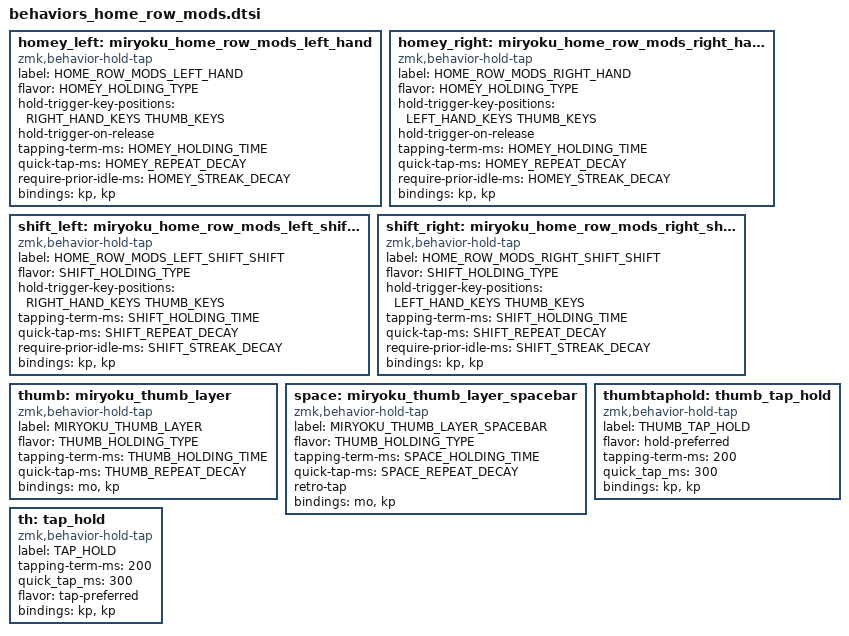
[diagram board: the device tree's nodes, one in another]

    #define L_PINKY homey_left LGUI
    #define L_RING  homey_left LALT
    #define L_LONG  homey_left LCTRL
    #define L_INDEX shift_left LSHFT

    #define R_PINKY homey_right LGUI
    #define R_RING  homey_right LALT
    #define R_LONG  homey_right LCTRL
    #define R_INDEX shift_right LSHFT

    //
    // HOMEY_HOLDING_TYPE defines the flavor of ZMK hold-tap behavior to use
    // for the pinky, ring, and middle fingers (which are assigned to Super,
    // Alt, and Ctrl respectively in the Miryoku system) on home row keys.
    //
    #ifndef HOMEY_HOLDING_TYPE
    #define HOMEY_HOLDING_TYPE "tap-preferred"
    #endif

    //
    // HOMEY_HOLDING_TIME defines how long you need to hold (milliseconds)
    // home row mod keys in order to send their modifiers to the computer
    // (i.e. "register" them) for mod-click mouse usage (e.g. Ctrl-Click).
    //
    #ifndef HOMEY_HOLDING_TIME
    #define HOMEY_HOLDING_TIME 300 // TAPPING_TERM + ALLOW_CROSSOVER_AFTER
    #endif

    //
    // HOMEY_STREAK_DECAY defines how long you need to wait (milliseconds)
    // after typing before you can use home row mods again.  It prevents
    // unintended activation of home row mods when you're actively typing.
    //
    #ifndef HOMEY_STREAK_DECAY
    #define HOMEY_STREAK_DECAY 170 // global-quick-tap-ms
    #endif

    //
    // HOMEY_REPEAT_DECAY defines how much time you have left (milliseconds)
    // after tapping a key to hold it again in order to make it auto-repeat.
    //
    #ifndef HOMEY_REPEAT_DECAY
    #define HOMEY_REPEAT_DECAY 300 // "tap then hold" for key auto-repeat
    #endif

    //
    // SHIFT_HOLDING_TYPE defines the flavor of ZMK hold-tap behavior to use
    // for index fingers (which Miryoku assigns to Shift) on home row keys.
    //
    // NOTE: The "tap-preferred" flavor of ZMK hold-tap for index finger keys
    // allows faster activation of the Shift modifier (without having to wait
    // for the modified key to be released as the "balanced" flavor requires).
    // Typing streaks and the `hold-trigger-on-release` setting are disabled
    // for the index fingers so as not to hinder their speed and dexterity.
    //
    #ifndef SHIFT_HOLDING_TYPE
    #define SHIFT_HOLDING_TYPE "tap-preferred"
    #endif

    //
    // SHIFT_HOLDING_TIME defines how long you need to hold (milliseconds)
    // index finger keys in order to send their modifiers to the computer
    // (i.e. "register" them) for mod-click mouse usage (e.g. Shift-Click).
    //
    // CAUTION: You'll need to perform inward rolls from pinky->ring->middle
    // fingers toward the index fingers when activating multiple modifiers
    // because `hold-trigger-on-release` is disabled for the index fingers.
    // Otherwise, you may be surprised that the index fingers' modifier is
    // sent immediately without the rest of your multi-mod chord when you
    // perform outward rolls from your index fingers toward your pinkies.
    //
    #ifndef SHIFT_HOLDING_TIME
    #define SHIFT_HOLDING_TIME 220
    #endif

    //
    // SHIFT_STREAK_DECAY defines how long you need to wait (milliseconds)
    // after typing before you can use home row mods again.  It prevents
    // unintended activation of home row mods when you're actively typing.
    //
    #ifndef SHIFT_STREAK_DECAY
    #define SHIFT_STREAK_DECAY 150 // global-quick-tap-ms
    #endif

    //
    // SHIFT_REPEAT_DECAY defines how much time you have left (milliseconds)
    // after tapping a key to hold it again in order to make it auto-repeat.
    //
    #ifndef SHIFT_REPEAT_DECAY
    #define SHIFT_REPEAT_DECAY 300 // "tap then hold" for key auto-repeat
    #endif

    //
    // THUMB_HOLDING_TYPE defines the flavor of ZMK hold-tap behavior to use
    // for the thumbs (which are assigned to 6 layers in the Miryoku system).
    //
    // NOTE: The "balanced" flavor of ZMK hold-tap provides instant modifier
    // activation for the symbol layer (if the tapped symbol key is released
    // while the thumb layer key is still held down) for quicker programming.
    //
    #ifndef THUMB_HOLDING_TYPE
    #define THUMB_HOLDING_TYPE "balanced"
    #endif

    //
    // THUMB_HOLDING_TIME defines how long you need to hold (milliseconds)
    // a thumb key to activate a layer.  Shorter holds are treated as taps.
    //
    #ifndef THUMB_HOLDING_TIME
    #define THUMB_HOLDING_TIME 200
    #endif

    //
    // THUMB_REPEAT_DECAY defines how much time you have left (milliseconds)
    // after tapping a key to hold it again in order to make it auto-repeat.
    //
    #ifndef THUMB_REPEAT_DECAY
    #define THUMB_REPEAT_DECAY 300 // "tap then hold" for key auto-repeat
    #endif

    //
    // SPACE_HOLDING_TIME defines how long you need to hold (milliseconds)
    // the space thumb key to activate.  Shorter holds are treated as taps.
    //
    #ifndef SPACE_HOLDING_TIME
    #define SPACE_HOLDING_TIME 200
    #endif

    //
    // SPACE_REPEAT_DECAY defines how much time you have left (milliseconds)
    // after tapping a key to hold it again in order to make it auto-repeat.
    //
    #ifndef SPACE_REPEAT_DECAY
    #define SPACE_REPEAT_DECAY 200 // "tap then hold" for key auto-repeat
    #endif

    //
    // Advantage 360 Pro key positions index for positional hold-tap
    //
    // |------------------------|------------------------|
    // | LEFT_HAND_KEYS         |        RIGHT_HAND_KEYS |
    // |                        |                        |
    // |  0  1  2  3  4  5  6   |   7  8  9  10 11 12 13 |
    // | 14 15 16 17 18 19 20   |   21 22 23 24 25 26 27 |
    // | 28 29 30 31 32 33 34   |   39 40 41 42 43 44 45 |
    // | 46 47 48 49 50 51      |      54 55 56 57 58 59 |
    // | 60 61 62 63 64         |         71 72 73 74 75 |
    // |                  35 36 | 37 38                  |
    // |               65 66 52 | 53 69 70               |
    // |               65 66 67 | 68 69 70               |
    // |------------------------|------------------------|
    //
    #define LEFT_HAND_KEYS      \
          0  1  2  3  4  5  6   \
          14 15 16 17 18 19 20  \
          28 29 30 31 32 33 34  \
          46 47 48 49 50 51     \
          60 61 62 63 64
    #define RIGHT_HAND_KEYS     \
                                    7  8  9 10 11 12 13  \ 
                                    21 22 23 24 25 26 27 \
                                    39 40 41 42 43 44 45 \
                                       54 55 56 57 58 59 \
                                          71 72 73 74 75
    #define THUMB_KEYS          \
                          35 36   37 38      \
                             52   53         \
                       65 66 67   68 69 70


    //
    // Home row mod-tap keys for all except index fingers
    //
    homey_left: miryoku_home_row_mods_left_hand {
        compatible = "zmk,behavior-hold-tap";
        label = "HOME_ROW_MODS_LEFT_HAND";
        flavor = HOMEY_HOLDING_TYPE;
        hold-trigger-key-positions = <RIGHT_HAND_KEYS THUMB_KEYS>;
        hold-trigger-on-release; // wait for other home row mods
        tapping-term-ms = <HOMEY_HOLDING_TIME>;
        quick-tap-ms = <HOMEY_REPEAT_DECAY>;
        require-prior-idle-ms = <HOMEY_STREAK_DECAY>;
        #binding-cells = <2>;
        bindings = <&kp>, <&kp>;
    };
    homey_right: miryoku_home_row_mods_right_hand {
        compatible = "zmk,behavior-hold-tap";
        label = "HOME_ROW_MODS_RIGHT_HAND";
        flavor = HOMEY_HOLDING_TYPE;
        hold-trigger-key-positions = <LEFT_HAND_KEYS THUMB_KEYS>;
        hold-trigger-on-release; // wait for other home row mods
        tapping-term-ms = <HOMEY_HOLDING_TIME>;
        quick-tap-ms = <HOMEY_REPEAT_DECAY>;
        require-prior-idle-ms = <HOMEY_STREAK_DECAY>;
        #binding-cells = <2>;
        bindings = <&kp>, <&kp>;
    };

    //
    // Special home row mod-tap keys for the index fingers
    //
    shift_left: miryoku_home_row_mods_left_shift_shift {
        compatible = "zmk,behavior-hold-tap";
        label = "HOME_ROW_MODS_LEFT_SHIFT_SHIFT";
        flavor = SHIFT_HOLDING_TYPE;
        hold-trigger-key-positions = <RIGHT_HAND_KEYS THUMB_KEYS>;
        //hold-trigger-on-release; // don't wait for other mods
        tapping-term-ms = <SHIFT_HOLDING_TIME>;
        quick-tap-ms = <SHIFT_REPEAT_DECAY>;
        require-prior-idle-ms = <SHIFT_STREAK_DECAY>;
        #binding-cells = <2>;
        bindings = <&kp>, <&kp>;
    };
    shift_right: miryoku_home_row_mods_right_shift_shift {
        compatible = "zmk,behavior-hold-tap";
        label = "HOME_ROW_MODS_RIGHT_SHIFT_SHIFT";
        flavor = SHIFT_HOLDING_TYPE;
        hold-trigger-key-positions = <LEFT_HAND_KEYS THUMB_KEYS>;
        //hold-trigger-on-release; // don't wait for other mods
        tapping-term-ms = <SHIFT_HOLDING_TIME>;
        quick-tap-ms = <SHIFT_REPEAT_DECAY>;
        require-prior-idle-ms = <SHIFT_STREAK_DECAY>;
        #binding-cells = <2>;
        bindings = <&kp>, <&kp>;
    };

    //
    // Thumb cluster hold-tap keys for Miryoku layers
    //
    thumb: miryoku_thumb_layer {
        compatible = "zmk,behavior-hold-tap";
        label = "MIRYOKU_THUMB_LAYER";
        flavor = THUMB_HOLDING_TYPE;
        tapping-term-ms = <THUMB_HOLDING_TIME>;
        quick-tap-ms = <THUMB_REPEAT_DECAY>; // enable repeat
        //global-quick-tap; // no typing streak
        //retro-tap; // don't allow slow (hold-like) taps
        #binding-cells = <2>;
        bindings = <&mo>, <&kp>;
    };
    space: miryoku_thumb_layer_spacebar {
        compatible = "zmk,behavior-hold-tap";
        label = "MIRYOKU_THUMB_LAYER_SPACEBAR";
        flavor = THUMB_HOLDING_TYPE;
        tapping-term-ms = <SPACE_HOLDING_TIME>;
        quick-tap-ms = <SPACE_REPEAT_DECAY>; // enable repeat
        //global-quick-tap; // no typing streak
        retro-tap; // allow slow (hold-like) taps
        #binding-cells = <2>;
        bindings = <&mo>, <&kp>;
    };


    thumbtaphold: thumb_tap_hold {
        compatible = "zmk,behavior-hold-tap";
        label = "THUMB_TAP_HOLD";
        flavor = "hold-preferred";
        tapping-term-ms = <200>;
        quick_tap_ms = <300>;
        // retro-tap; // allow slow (hold-like) taps
        #binding-cells = <2>;
        bindings = <&kp>, <&kp>;
    };

    th: tap_hold { // like hold-tap, but prio for tap
        compatible = "zmk,behavior-hold-tap";
        label = "TAP_HOLD";
        #binding-cells = <2>;
        tapping-term-ms = <200>;
        quick_tap_ms = <300>;
        flavor = "tap-preferred";
        bindings = <&kp>, <&kp>;
    };

